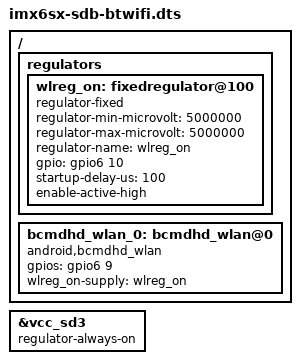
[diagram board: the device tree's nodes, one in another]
/*
 * Copyright (C) 2015 Freescale Semiconductor, Inc.
 *
 * This program is free software; you can redistribute it and/or modify
 * it under the terms of the GNU General Public License version 2 as
 * published by the Free Software Foundation.
 */

/*
 * NOTE: This DTS file is written for plugging in Murata Wi-Fi/BT EVK into SD3
 * slot using Murata i.MX InterConnect Ver 1.0 Adapter AND SD Card Extender on
 * SD2 slot. Bluetooth UART connects via SD3 EMMC/MMC Plus pinout.
 * WL_REG_ON/BT_REG_ON/WL_HOST_WAKE connect via SD Card Extender.
 */

#include "imx6sx-sdb.dts"

/ {
	regulators {
		wlreg_on: fixedregulator@100 {
			compatible = "regulator-fixed";
			regulator-min-microvolt = <5000000>;
			regulator-max-microvolt = <5000000>;
			regulator-name = "wlreg_on";
			gpio = <&gpio6 10 0>;
			startup-delay-us = <100>;
			enable-active-high;
		};
	};

	bcmdhd_wlan_0: bcmdhd_wlan@0 {
		compatible = "android,bcmdhd_wlan";
		/* WL_HOST_WAKE: SD2_DAT1 (gpio6 9) */
		gpios = <&gpio6 9 0>;
		wlreg_on-supply = <&wlreg_on>;
	};
};

&vcc_sd3 {
	regulator-always-on;
};


